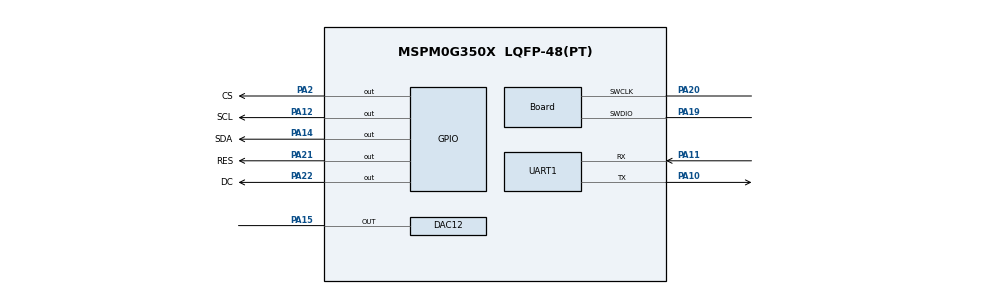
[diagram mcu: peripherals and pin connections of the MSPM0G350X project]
/**
 * @cliArgs --device "MSPM0G350X" --part "Default" --package "LQFP-48(PT)" --product "mspm0_sdk@2.03.00.08"
 * @versions {"tool":"1.21.1+3772"}
 */

/**
 * Import the modules used in this configuration.
 */
const DAC12   = scripting.addModule("/ti/driverlib/DAC12");
const GPIO    = scripting.addModule("/ti/driverlib/GPIO", {}, false);
const GPIO1   = GPIO.addInstance();
const SYSCTL  = scripting.addModule("/ti/driverlib/SYSCTL");
const SYSTICK = scripting.addModule("/ti/driverlib/SYSTICK");
const UART    = scripting.addModule("/ti/driverlib/UART", {}, false);
const UART1   = UART.addInstance();

/**
 * Write custom configuration values to the imported modules.
 */
const gate7  = system.clockTree["MFCLKGATE"];
gate7.enable = true;

const gate8  = system.clockTree["MFPCLKGATE"];
gate8.enable = true;

DAC12.dacAmplifier              = "ON";
DAC12.dacOutputPinEn            = true;
DAC12.peripheral.$assign        = "DAC0";
DAC12.peripheral.OutPin.$assign = "PA15";
DAC12.OutPinConfig.$name        = "ti_driverlib_gpio_GPIOPinGeneric2";

const Board                       = scripting.addModule("/ti/driverlib/Board", {}, false);
Board.peripheral.$assign          = "DEBUGSS";
Board.peripheral.swclkPin.$assign = "PA20";
Board.peripheral.swdioPin.$assign = "PA19";

GPIO1.$name                          = "GPIO";
GPIO1.port                           = "PORTA";
GPIO1.associatedPins.create(5);
GPIO1.associatedPins[0].$name        = "SCL";
GPIO1.associatedPins[0].initialValue = "SET";
GPIO1.associatedPins[0].assignedPin  = "12";
GPIO1.associatedPins[0].pin.$assign  = "PA12";
GPIO1.associatedPins[1].$name        = "SDA";
GPIO1.associatedPins[1].initialValue = "SET";
GPIO1.associatedPins[1].assignedPin  = "14";
GPIO1.associatedPins[1].pin.$assign  = "PA14";
GPIO1.associatedPins[2].$name        = "RES";
GPIO1.associatedPins[2].initialValue = "SET";
GPIO1.associatedPins[2].assignedPin  = "21";
GPIO1.associatedPins[2].pin.$assign  = "PA21";
GPIO1.associatedPins[3].$name        = "DC";
GPIO1.associatedPins[3].initialValue = "SET";
GPIO1.associatedPins[3].assignedPin  = "22";
GPIO1.associatedPins[3].pin.$assign  = "PA22";
GPIO1.associatedPins[4].$name        = "CS";
GPIO1.associatedPins[4].initialValue = "SET";
GPIO1.associatedPins[4].assignedPin  = "2";
GPIO1.associatedPins[4].pin.$assign  = "PA2";

SYSCTL.forceDefaultClkConfig = true;
SYSCTL.clockTreeEn           = true;
SYSCTL.MFPCLKEn              = true;

SYSTICK.periodEnable      = true;
SYSTICK.systickEnable     = true;
SYSTICK.interruptPriority = "0";
SYSTICK.period            = 32;

UART1.$name                    = "UART_0";
UART1.uartClkSrc               = "MFCLK";
UART1.enabledInterrupts        = ["RX"];
UART1.peripheral.$assign       = "UART0";
UART1.peripheral.rxPin.$assign = "PA11";
UART1.peripheral.txPin.$assign = "PA10";
UART1.txPinConfig.$name        = "ti_driverlib_gpio_GPIOPinGeneric0";
UART1.rxPinConfig.$name        = "ti_driverlib_gpio_GPIOPinGeneric1";

const ProjectConfig              = scripting.addModule("/ti/project_config/ProjectConfig", {}, false);
ProjectConfig.migrationCondition = true;
